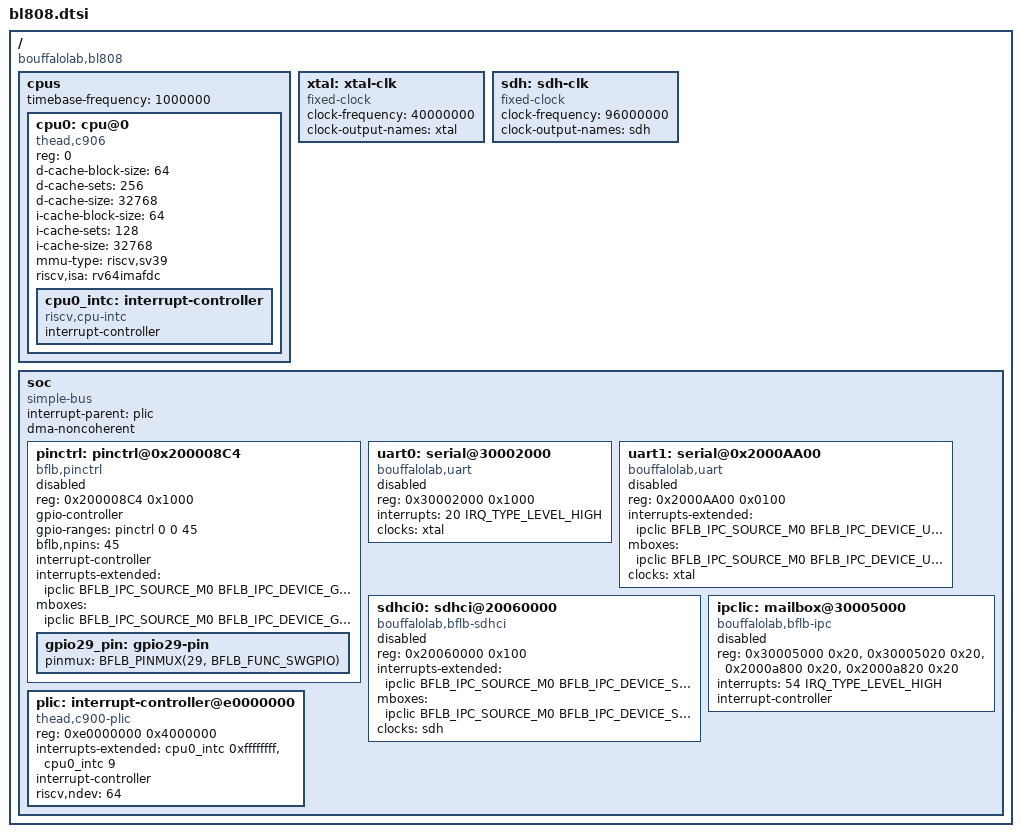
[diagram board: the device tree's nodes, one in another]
// SPDX-License-Identifier: (GPL-2.0+ or MIT)
/*
 * Copyright (C) 2022 Jisheng Zhang <jszhang@kernel.org>
 */

#include <dt-bindings/interrupt-controller/irq.h>
#include <dt-bindings/mailbox/bflb-ipc.h>
#include <dt-bindings/pinctrl/bflb.h>

/ {
	compatible = "bouffalolab,bl808";
	#address-cells = <1>;
	#size-cells = <1>;

	cpus {
		timebase-frequency = <1000000>;
		#address-cells = <1>;
		#size-cells = <0>;

		cpu0: cpu@0 {
			compatible = "thead,c906", "riscv";
			device_type = "cpu";
			reg = <0>;
			d-cache-block-size = <64>;
			d-cache-sets = <256>;
			d-cache-size = <32768>;
			i-cache-block-size = <64>;
			i-cache-sets = <128>;
			i-cache-size = <32768>;
			mmu-type = "riscv,sv39";
			riscv,isa = "rv64imafdc";

			cpu0_intc: interrupt-controller {
				compatible = "riscv,cpu-intc";
				interrupt-controller;
				#address-cells = <0>;
				#interrupt-cells = <1>;
			};
		};
	};

	xtal: xtal-clk {
		compatible = "fixed-clock";
		clock-frequency = <40000000>;
		clock-output-names = "xtal";
		#clock-cells = <0>;
	};

	sdh: sdh-clk {
		compatible = "fixed-clock";
		clock-frequency = <96000000>;
		clock-output-names = "sdh";
		#clock-cells = <0>;
	};

	soc {
		compatible = "simple-bus";
		ranges;
		interrupt-parent = <&plic>;
		dma-noncoherent;
		#address-cells = <1>;
		#size-cells = <1>;

		pinctrl: pinctrl@0x200008C4 {
			compatible = "bflb,pinctrl";
			reg = <0x200008C4 0x1000>; //Last register is for gpio_cfg141 at 0x20000af8
			//clocks = <&gpio_clk>;

			gpio-controller;
			#gpio-cells = <2>;
			gpio-ranges = <&pinctrl 0 0 45>;
			bflb,npins = <45>;

			status = "disabled";

			interrupt-controller;
			#interrupt-cells = <2>;
			//interrupt-parent = <&aic>;
			interrupts-extended = <&ipclic BFLB_IPC_SOURCE_M0
								BFLB_IPC_DEVICE_GPIO
								IRQ_TYPE_EDGE_RISING>;
			mboxes = <&ipclic BFLB_IPC_SOURCE_M0 BFLB_IPC_DEVICE_GPIO>;
			/*interrupts = <AIC_IRQ 16 IRQ_TYPE_LEVEL_HIGH>,
						<AIC_IRQ 17 IRQ_TYPE_LEVEL_HIGH>,
						<AIC_IRQ 18 IRQ_TYPE_LEVEL_HIGH>,
						<AIC_IRQ 19 IRQ_TYPE_LEVEL_HIGH>,
						<AIC_IRQ 20 IRQ_TYPE_LEVEL_HIGH>,
						<AIC_IRQ 21 IRQ_TYPE_LEVEL_HIGH>,
						<AIC_IRQ 22 IRQ_TYPE_LEVEL_HIGH>;*/

			/*pcie_pins: pcie-pins {
				pinmux = <APPLE_PINMUX(150, 1)>,
						<APPLE_PINMUX(151, 1)>,
						<APPLE_PINMUX(32, 1)>;
			};*/

			gpio29_pin: gpio29-pin {
				pinmux = <BFLB_PINMUX(29, BFLB_FUNC_SWGPIO)>;
			};
		};

		uart0: serial@30002000 {
			compatible = "bouffalolab,uart";
			reg = <0x30002000 0x1000>;
			interrupts = <20 IRQ_TYPE_LEVEL_HIGH>;
			clocks = <&xtal>;
			status = "disabled";
		};
		
		uart1: serial@0x2000AA00 {
			compatible = "bouffalolab,uart";
			reg = <0x2000AA00 0x0100>;
			interrupts-extended = <&ipclic BFLB_IPC_SOURCE_M0
								BFLB_IPC_DEVICE_UART2
								IRQ_TYPE_EDGE_RISING>;
			mboxes = <&ipclic BFLB_IPC_SOURCE_M0 BFLB_IPC_DEVICE_UART2>;
			clocks = <&xtal>;
			status = "disabled";
		};
		
		sdhci0: sdhci@20060000 {
			compatible = "bouffalolab,bflb-sdhci";
			reg = <0x20060000 0x100>;
			interrupts-extended = <&ipclic BFLB_IPC_SOURCE_M0
						       BFLB_IPC_DEVICE_SDHCI
						       IRQ_TYPE_EDGE_RISING>;
			mboxes = <&ipclic BFLB_IPC_SOURCE_M0 BFLB_IPC_DEVICE_SDHCI>;
			clocks = <&sdh>;
			status = "disabled";
		};

		ipclic: mailbox@30005000 {
			compatible = "bouffalolab,bflb-ipc";
			reg = <0x30005000 0x20>,
			      <0x30005020 0x20>,
			      <0x2000a800 0x20>,
			      <0x2000a820 0x20>;
			interrupts = <54 IRQ_TYPE_LEVEL_HIGH>;
			interrupt-controller;
			#interrupt-cells = <3>;
			#mbox-cells = <2>;
			status = "disabled";
		};

		plic: interrupt-controller@e0000000 {
			compatible = "thead,c900-plic";
			reg = <0xe0000000 0x4000000>;
			interrupts-extended = <&cpu0_intc 0xffffffff>,
					      <&cpu0_intc 9>;
			interrupt-controller;
			#address-cells = <0>;
			#interrupt-cells = <2>;
			riscv,ndev = <64>;
		};
	};
};
